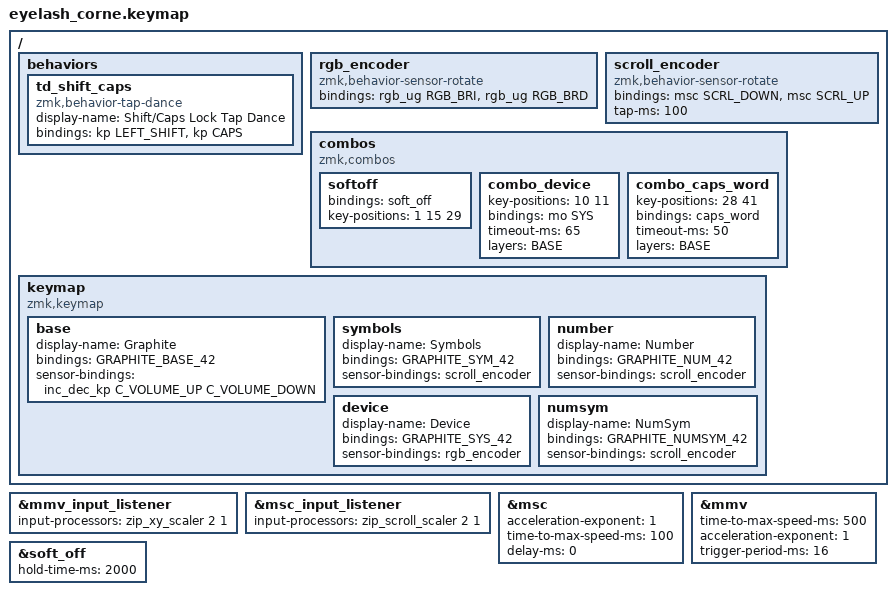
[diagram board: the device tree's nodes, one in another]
/*
 * Eyelash Corne with Graphite layout
 */

#define ZMK_POINTING_DEFAULT_MOVE_VAL 1200
#define ZMK_POINTING_DEFAULT_SCRL_VAL 25

#include <input/processors.dtsi>
#include <zephyr/dt-bindings/input/input-event-codes.h>
#include <behaviors.dtsi>
#include <dt-bindings/zmk/bt.h>
#include <dt-bindings/zmk/keys.h>
#include <dt-bindings/zmk/outputs.h>
#include <dt-bindings/zmk/pointing.h>
#include <dt-bindings/zmk/rgb.h>

#include "graphite.dtsi"

&mmv_input_listener { input-processors = <&zip_xy_scaler 2 1>; };
&msc_input_listener { input-processors = <&zip_scroll_scaler 2 1>; };

&msc {
    acceleration-exponent = <1>;
    time-to-max-speed-ms = <100>;
    delay-ms = <0>;
};

&mmv {
    time-to-max-speed-ms = <500>;
    acceleration-exponent = <1>;
    trigger-period-ms = <16>;
};

&soft_off { hold-time-ms = <2000>; };

/ {
    behaviors {
        td_shift_caps: td_shift_caps {
            compatible = "zmk,behavior-tap-dance";
            display-name = "Shift/Caps Lock Tap Dance";
            #binding-cells = <0>;
            bindings = <&kp LEFT_SHIFT>, <&kp CAPS>;
        };
    };

    rgb_encoder: rgb_encoder {
        compatible = "zmk,behavior-sensor-rotate";
        #sensor-binding-cells = <0>;
        bindings = <&rgb_ug RGB_BRI>, <&rgb_ug RGB_BRD>;
    };

    scroll_encoder: scroll_encoder {
        compatible = "zmk,behavior-sensor-rotate";
        #sensor-binding-cells = <0>;
        bindings = <&msc SCRL_DOWN>, <&msc SCRL_UP>;
        tap-ms = <100>;
    };

    combos {
        compatible = "zmk,combos";

        softoff {
            bindings = <&soft_off>;
            key-positions = <1 15 29>;
        };

        // U+J: hold for Device layer
        combo_device {
            key-positions = <10 11>;
            bindings = <&mo SYS>;
            timeout-ms = <65>;
            layers = <BASE>;
        };

        // both shifts: caps word
        combo_caps_word {
            key-positions = <28 41>;
            bindings = <&caps_word>;
            timeout-ms = <50>;
            layers = <BASE>;
        };
    };

    keymap {
        compatible = "zmk,keymap";

        base {
            display-name = "Graphite";
            bindings = < GRAPHITE_BASE_42 >;
            sensor-bindings = <&inc_dec_kp C_VOLUME_UP C_VOLUME_DOWN>;
        };

        symbols {
            display-name = "Symbols";
            bindings = < GRAPHITE_SYM_42 >;
            sensor-bindings = <&scroll_encoder>;
        };

        number {
            display-name = "Number";
            bindings = < GRAPHITE_NUM_42 >;
            sensor-bindings = <&scroll_encoder>;
        };

        device {
            display-name = "Device";
            bindings = < GRAPHITE_SYS_42 >;
            sensor-bindings = <&rgb_encoder>;
        };

        numsym {
            display-name = "NumSym";
            bindings = < GRAPHITE_NUMSYM_42 >;
            sensor-bindings = <&scroll_encoder>;
        };
    };
};
